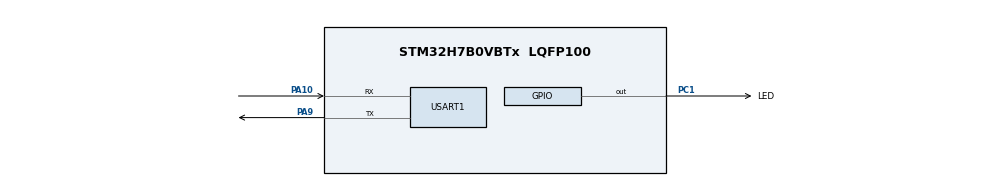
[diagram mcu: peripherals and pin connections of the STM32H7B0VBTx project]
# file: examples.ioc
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CORTEX_M7.default_mode_Activation=1
Mcu.Family=STM32H7
Mcu.Name=STM32H7B0VBTx
Mcu.Package=LQFP100
NVIC.PriorityGroup=NVIC_PRIORITYGROUP_4
PA10.Mode=Asynchronous
PA10.Signal=USART1_RX
PA9.Mode=Asynchronous
PA9.Signal=USART1_TX
PC1.GPIO_Label=LED
PC1.GPIO_ModeDefaultOutputPP=GPIO_MODE_OUTPUT_PP
PC1.GPIO_PuPd=GPIO_PULLUP
PC1.GPIO_Speed=GPIO_SPEED_FREQ_VERY_HIGH
PC1.Signal=GPIO_Output
PC14-OSC32_IN.Mode=LSE-External-Oscillator
PC14-OSC32_IN.Signal=RCC_OSC32_IN
PC15-OSC32_OUT.Mode=LSE-External-Oscillator
PC15-OSC32_OUT.Signal=RCC_OSC32_OUT
PH0-OSC_IN.Mode=HSE-External-Oscillator
PH0-OSC_IN.Signal=RCC_OSC_IN
PH1-OSC_OUT.Mode=HSE-External-Oscillator
PH1-OSC_OUT.Signal=RCC_OSC_OUT
ProjectManager.HeapSize=0x200
ProjectManager.StackSize=0x400
ProjectManager.TargetToolchain=CMake
RCC.ADCFreq_Value=50390625
RCC.APB1Freq_Value=140000000
RCC.APB2Freq_Value=140000000
RCC.APB3Freq_Value=140000000
RCC.APB4Freq_Value=140000000
RCC.CDPPRE=RCC_APB3_DIV2
RCC.CDPPRE1=RCC_APB1_DIV2
RCC.CDPPRE2=RCC_APB2_DIV2
RCC.CortexFreq_Value=280000000
RCC.DIVM1=5
RCC.DIVN1=112
RCC.HCLKFreq_Value=280000000
RCC.HSE_VALUE=25000000
RCC.PLLFRACN=0
RCC.PLLSourceVirtual=RCC_PLLSOURCE_HSE
RCC.SRDPPRE=RCC_APB4_DIV2
RCC.SYSCLKFreq_VALUE=280000000
RCC.SYSCLKSource=RCC_SYSCLKSOURCE_PLLCLK
RCC.USART16CLockSelection=RCC_USART16910CLKSOURCE_HSI
RCC.USBFreq_Value=280000000
USART1.VirtualMode-Asynchronous=VM_ASYNC
VP_MEMORYMAP_VS_MEMORYMAP.Mode=CurAppReg
board=custom

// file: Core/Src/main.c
/* USER CODE BEGIN Header */
/**
  ******************************************************************************
  * @file           : main.c
  * @brief          : Main program body
  ******************************************************************************
  * @attention
  *
  * Copyright (c) 2024 STMicroelectronics.
  * All rights reserved.
  *
  * This software is licensed under terms that can be found in the LICENSE file
  * in the root directory of this software component.
  * If no LICENSE file comes with this software, it is provided AS-IS.
  *
  ******************************************************************************
  */
/* USER CODE END Header */
#include "main.h"

UART_HandleTypeDef huart1;

void SystemClock_Config(void);
static void MPU_Config(void);
static void MX_GPIO_Init(void);
static void MX_USART1_UART_Init(void);
/* USER CODE BEGIN PFP */
extern void app(void);
/* USER CODE END PFP */

int main(void)
{

  /* MPU Configuration--------------------------------------------------------*/
  MPU_Config();

  /* MCU Configuration--------------------------------------------------------*/

  /* Reset of all peripherals, Initializes the Flash interface and the Systick. */
  HAL_Init();

  /* USER CODE BEGIN Init */
  RCC_ClkInitTypeDef RCC_ClkInitStruct = {0};
  // 先将时钟源选择为内部时钟
  RCC_ClkInitStruct.ClockType = RCC_CLOCKTYPE_SYSCLK;
  RCC_ClkInitStruct.SYSCLKSource = RCC_SYSCLKSOURCE_HSI;
  if (HAL_RCC_ClockConfig(&RCC_ClkInitStruct, FLASH_LATENCY_5) != HAL_OK)
  {
      Error_Handler();
  }
  /* USER CODE END Init */

  /* Configure the system clock */
  SystemClock_Config();

  /* Initialize all configured peripherals */
  MX_GPIO_Init();
  MX_USART1_UART_Init();

  /* Infinite loop */
  /* USER CODE BEGIN WHILE */
  app();
  while (1)
  {
    /* USER CODE END WHILE */

  }
}

void SystemClock_Config(void)
{
  RCC_OscInitTypeDef RCC_OscInitStruct = {0};
  RCC_ClkInitTypeDef RCC_ClkInitStruct = {0};

  /*AXI clock gating */
  RCC->CKGAENR = 0xFFFFFFFF;

  /** Supply configuration update enable
  */
  HAL_PWREx_ConfigSupply(PWR_LDO_SUPPLY);

  /** Configure the main internal regulator output voltage
  */
  __HAL_PWR_VOLTAGESCALING_CONFIG(PWR_REGULATOR_VOLTAGE_SCALE0);

  while(!__HAL_PWR_GET_FLAG(PWR_FLAG_VOSRDY)) {}

  /** Initializes the RCC Oscillators according to the specified parameters
  * in the RCC_OscInitTypeDef structure.
  */
  RCC_OscInitStruct.OscillatorType = RCC_OSCILLATORTYPE_HSI|RCC_OSCILLATORTYPE_HSE;
  RCC_OscInitStruct.HSEState = RCC_HSE_ON;
  RCC_OscInitStruct.HSIState = RCC_HSI_DIV1;
  RCC_OscInitStruct.HSICalibrationValue = 64;
  RCC_OscInitStruct.PLL.PLLState = RCC_PLL_ON;
  RCC_OscInitStruct.PLL.PLLSource = RCC_PLLSOURCE_HSE;
  RCC_OscInitStruct.PLL.PLLM = 5;
  RCC_OscInitStruct.PLL.PLLN = 112;
  RCC_OscInitStruct.PLL.PLLP = 2;
  RCC_OscInitStruct.PLL.PLLQ = 2;
  RCC_OscInitStruct.PLL.PLLR = 2;
  RCC_OscInitStruct.PLL.PLLRGE = RCC_PLL1VCIRANGE_2;
  RCC_OscInitStruct.PLL.PLLVCOSEL = RCC_PLL1VCOWIDE;
  RCC_OscInitStruct.PLL.PLLFRACN = 0;
  if (HAL_RCC_OscConfig(&RCC_OscInitStruct) != HAL_OK)
  {
    Error_Handler();
  }

  /** Initializes the CPU, AHB and APB buses clocks
  */
  RCC_ClkInitStruct.ClockType = RCC_CLOCKTYPE_HCLK|RCC_CLOCKTYPE_SYSCLK
                              |RCC_CLOCKTYPE_PCLK1|RCC_CLOCKTYPE_PCLK2
                              |RCC_CLOCKTYPE_D3PCLK1|RCC_CLOCKTYPE_D1PCLK1;
  RCC_ClkInitStruct.SYSCLKSource = RCC_SYSCLKSOURCE_PLLCLK;
  RCC_ClkInitStruct.SYSCLKDivider = RCC_SYSCLK_DIV1;
  RCC_ClkInitStruct.AHBCLKDivider = RCC_HCLK_DIV1;
  RCC_ClkInitStruct.APB3CLKDivider = RCC_APB3_DIV2;
  RCC_ClkInitStruct.APB1CLKDivider = RCC_APB1_DIV2;
  RCC_ClkInitStruct.APB2CLKDivider = RCC_APB2_DIV2;
  RCC_ClkInitStruct.APB4CLKDivider = RCC_APB4_DIV2;

  if (HAL_RCC_ClockConfig(&RCC_ClkInitStruct, FLASH_LATENCY_6) != HAL_OK)
  {
    Error_Handler();
  }
}

static void MX_USART1_UART_Init(void)
{

  huart1.Instance = USART1;
  huart1.Init.BaudRate = 115200;
  huart1.Init.WordLength = UART_WORDLENGTH_8B;
  huart1.Init.StopBits = UART_STOPBITS_1;
  huart1.Init.Parity = UART_PARITY_NONE;
  huart1.Init.Mode = UART_MODE_TX_RX;
  huart1.Init.HwFlowCtl = UART_HWCONTROL_NONE;
  huart1.Init.OverSampling = UART_OVERSAMPLING_16;
  huart1.Init.OneBitSampling = UART_ONE_BIT_SAMPLE_DISABLE;
  huart1.Init.ClockPrescaler = UART_PRESCALER_DIV1;
  huart1.AdvancedInit.AdvFeatureInit = UART_ADVFEATURE_NO_INIT;
  if (HAL_UART_Init(&huart1) != HAL_OK)
  {
    Error_Handler();
  }
  if (HAL_UARTEx_SetTxFifoThreshold(&huart1, UART_TXFIFO_THRESHOLD_1_8) != HAL_OK)
  {
    Error_Handler();
  }
  if (HAL_UARTEx_SetRxFifoThreshold(&huart1, UART_RXFIFO_THRESHOLD_1_8) != HAL_OK)
  {
    Error_Handler();
  }
  if (HAL_UARTEx_DisableFifoMode(&huart1) != HAL_OK)
  {
    Error_Handler();
  }

}

static void MX_GPIO_Init(void)
{
  GPIO_InitTypeDef GPIO_InitStruct = {0};

  /* GPIO Ports Clock Enable */
  __HAL_RCC_GPIOC_CLK_ENABLE();
  __HAL_RCC_GPIOH_CLK_ENABLE();
  __HAL_RCC_GPIOA_CLK_ENABLE();

  /*Configure GPIO pin Output Level */
  HAL_GPIO_WritePin(LED_GPIO_Port, LED_Pin, GPIO_PIN_RESET);

  /*Configure GPIO pin : LED_Pin */
  GPIO_InitStruct.Pin = LED_Pin;
  GPIO_InitStruct.Mode = GPIO_MODE_OUTPUT_PP;
  GPIO_InitStruct.Pull = GPIO_PULLUP;
  GPIO_InitStruct.Speed = GPIO_SPEED_FREQ_VERY_HIGH;
  HAL_GPIO_Init(LED_GPIO_Port, &GPIO_InitStruct);

}

 /* MPU Configuration */

void MPU_Config(void)
{
  MPU_Region_InitTypeDef MPU_InitStruct = {0};

  /* Disables the MPU */
  HAL_MPU_Disable();

  /** Initializes and configures the Region and the memory to be protected
  */
  MPU_InitStruct.Enable = MPU_REGION_ENABLE;
  MPU_InitStruct.Number = MPU_REGION_NUMBER0;
  MPU_InitStruct.BaseAddress = 0x0;
  MPU_InitStruct.Size = MPU_REGION_SIZE_4GB;
  MPU_InitStruct.SubRegionDisable = 0x87;
  MPU_InitStruct.TypeExtField = MPU_TEX_LEVEL0;
  MPU_InitStruct.AccessPermission = MPU_REGION_NO_ACCESS;
  MPU_InitStruct.DisableExec = MPU_INSTRUCTION_ACCESS_DISABLE;
  MPU_InitStruct.IsShareable = MPU_ACCESS_SHAREABLE;
  MPU_InitStruct.IsCacheable = MPU_ACCESS_NOT_CACHEABLE;
  MPU_InitStruct.IsBufferable = MPU_ACCESS_NOT_BUFFERABLE;

  HAL_MPU_ConfigRegion(&MPU_InitStruct);
  /* Enables the MPU */
  HAL_MPU_Enable(MPU_PRIVILEGED_DEFAULT);

}

void Error_Handler(void)
{
  __disable_irq();
  while (1)
  {
  }
}
